# STM8L151K4 register map
Vendor: STMicroelectronics; Series: STM8L/STM8AL, medium density; File version: 1.0
CPU: other r1p0, big endian, no MPU, no FPU, 4 interrupt priority bits
Registers are 8-bit, read-write, reset 0x0 unless marked. A register's access mark holds for its fields unless they carry their own. Offsets are from the block's base; [hi:lo] are bit positions; {n}, {i} and the like mark numbered series.

## FLASH
Base 0x00005050
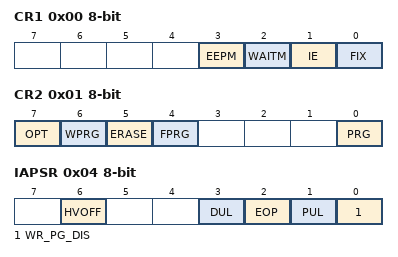
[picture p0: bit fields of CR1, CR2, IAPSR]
0x00 CR1 — Flash control register 1
  [3] EEPM, [2] WAITM, [1] IE, [0] FIX
0x01 CR2 — Flash control register 2
  [7] OPT, [6] WPRG, [5] ERASE, [4] FPRG, [0] PRG
0x02 PUKR — Flash program memory unprotection key register
  [7:0] MASS_PRG
0x03 DUKR — Data EEPROM unprotection key register
  [7:0] MASS_DATA
0x04 IAPSR — Flash in-application programming status register
  [6] HVOFF, [3] DUL, [2] EOP, [1] PUL, [0] WR_PG_DIS

## I2C1
Base 0x00005210
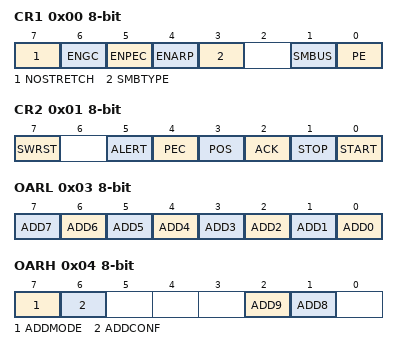
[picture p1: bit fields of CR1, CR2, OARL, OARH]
0x00 CR1 — I2C1 control register 1
  [7] NOSTRETCH, [6] ENGC, [5] ENPEC, [4] ENARP, [3] SMBTYPE, [1] SMBUS, [0] PE
0x01 CR2 — I2C1 control register 2
  [7] SWRST, [5] ALERT, [4] PEC, [3] POS, [2] ACK, [1] STOP, [0] START
0x02 FREQR — I2C1 frequency register
  [5:0] FREQ
0x03 OARL — I2C1 own address register low
  [n] ADD{n} (n=0..7)
0x04 OARH — I2C1 own address register high
  [7] ADDMODE, [6] ADDCONF, [2] ADD9, [1] ADD8
0x06 DR — I2C1 data register
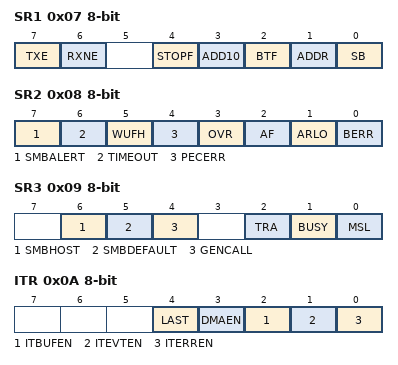
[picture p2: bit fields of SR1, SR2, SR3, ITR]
0x07 SR1 — I2C1 status register 1
  [7] TXE, [6] RXNE, [4] STOPF, [3] ADD10, [2] BTF, [1] ADDR, [0] SB
0x08 SR2 — I2C1 status register 2
  [7] SMBALERT, [6] TIMEOUT, [5] WUFH, [4] PECERR, [3] OVR, [2] AF, [1] ARLO, [0] BERR
0x09 SR3 — I2C1 status register 3
  [6] SMBHOST, [5] SMBDEFAULT, [4] GENCALL, [2] TRA, [1] BUSY, [0] MSL
0x0A ITR — I2C1 interrupt control register
  [4] LAST, [3] DMAEN, [2] ITBUFEN, [1] ITEVTEN, [0] ITERREN
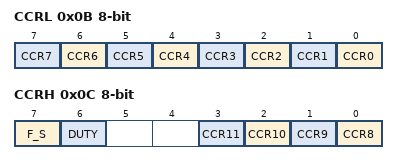
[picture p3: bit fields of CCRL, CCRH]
0x0B CCRL — I2C1 clock control register low
  [n] CCR{n} (n=0..7)
0x0C CCRH — I2C1 clock control register high
  [7] F_S, [6] DUTY, [n-8] CCR{n} (n=8..11)
0x0D TRISER reset 0x2 — I2C1 TRISE register
  [5:0] TRISE
0x0E PECR — I2C1 packet error checking register
  [7:0] PEC

## IRTIM
Base 0x000052FF
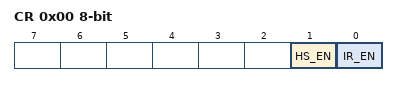
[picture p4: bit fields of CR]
0x00 CR — Infra-red control register
  [1] HS_EN, [0] IR_EN

## ITC_EXTI
Base 0x000050A0
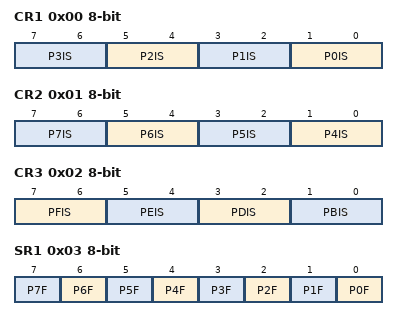
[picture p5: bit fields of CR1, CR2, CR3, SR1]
0x00 CR1 — External interrupt control register 1
  [2n+1:2n] P{n}IS (n=0..3)
0x01 CR2 — External interrupt control register 2
  [2n-7:2n-8] P{n}IS (n=4..7)
0x02 CR3 — External interrupt control register 3
  [7:6] PFIS, [5:4] PEIS, [3:2] PDIS, [1:0] PBIS
0x03 SR1 — External interrupt status register 1
  [n] P{n}F (n=0..7)
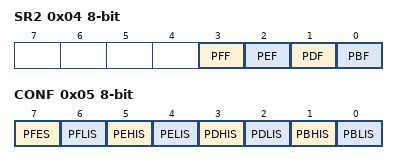
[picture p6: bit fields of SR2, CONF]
0x04 SR2 — External interrupt status register 2
  [3] PFF, [2] PEF, [1] PDF, [0] PBF
0x05 CONF — External interrupt port select register
  [7] PFES, [6] PFLIS, [5] PEHIS, [4] PELIS, [3] PDHIS, [2] PDLIS, [1] PBHIS, [0] PBLIS

## ITC_SPR
Base 0x00007F70
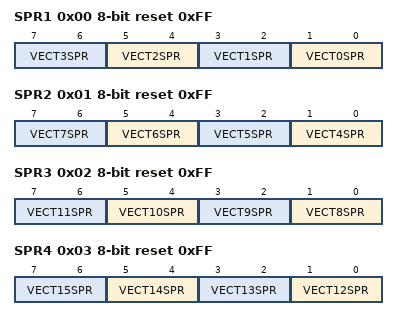
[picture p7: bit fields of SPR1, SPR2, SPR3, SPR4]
0x00 SPR1 reset 0xFF — Interrupt Software priority register 1
  [2n+1:2n] VECT{n}SPR (n=0..3)
0x01 SPR2 reset 0xFF — Interrupt Software priority register 2
  [2n-7:2n-8] VECT{n}SPR (n=4..7)
0x02 SPR3 reset 0xFF — Interrupt Software priority register 3
  [2n-15:2n-16] VECT{n}SPR (n=8..11)
0x03 SPR4 reset 0xFF — Interrupt Software priority register 4
  [2n-23:2n-24] VECT{n}SPR (n=12..15)
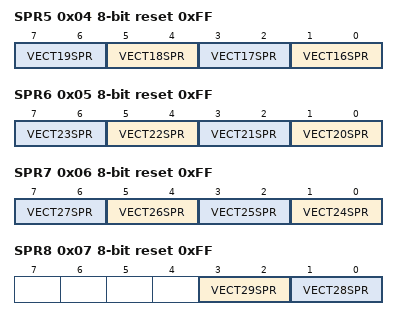
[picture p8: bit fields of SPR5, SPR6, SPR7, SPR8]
0x04 SPR5 reset 0xFF — Interrupt Software priority register 5
  [2n-31:2n-32] VECT{n}SPR (n=16..19)
0x05 SPR6 reset 0xFF — Interrupt Software priority register 6
  [2n-39:2n-40] VECT{n}SPR (n=20..23)
0x06 SPR7 reset 0xFF — Interrupt Software priority register 7
  [2n-47:2n-48] VECT{n}SPR (n=24..27)
0x07 SPR8 reset 0xFF — Interrupt Software priority register 8
  [3:2] VECT29SPR, [1:0] VECT28SPR

## IWDG
Base 0x000050E0
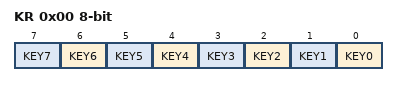
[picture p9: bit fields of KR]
0x00 KR — IWDG key register
  [n] KEY{n} (n=0..7)
0x01 PR — IWDG prescaler register
  [2:0] PR
0x02 RLR reset 0xFF — IWDG reload register
  [7:0] RL

## OPT
Base 0x00004800
0x00 OPT0 reset 0xAA — Read-out protection (ROP)
0x02 OPT1 — User boot code (UBC)
0x08 OPT3 — Watchdog option
0x09 OPT4 — Clock option
0x0A OPT5 — Brownout reset (BOR)
0x0B OPTBL_H — Bootloader (high byte)
0x0C OPTBL_L — Bootloader (low byte)
